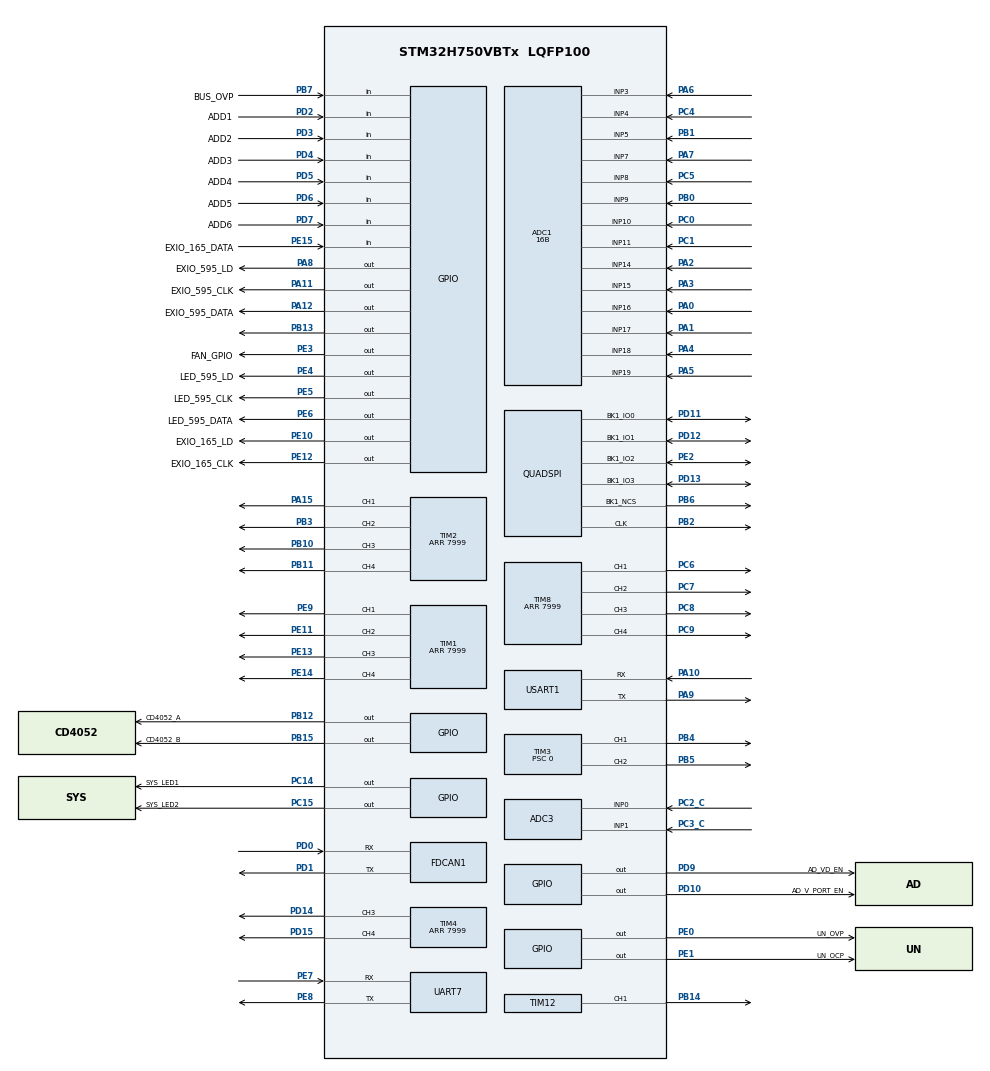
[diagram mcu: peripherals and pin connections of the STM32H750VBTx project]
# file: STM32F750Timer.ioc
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ADC1.Channel-1\#ChannelRegularConversion=ADC_CHANNEL_16
ADC1.Channel-10\#ChannelRegularConversion=ADC_CHANNEL_19
ADC1.Channel-11\#ChannelRegularConversion=ADC_CHANNEL_3
ADC1.Channel-12\#ChannelRegularConversion=ADC_CHANNEL_7
ADC1.Channel-13\#ChannelRegularConversion=ADC_CHANNEL_4
ADC1.Channel-14\#ChannelRegularConversion=ADC_CHANNEL_8
ADC1.Channel-15\#ChannelRegularConversion=ADC_CHANNEL_9
ADC1.Channel-16\#ChannelRegularConversion=ADC_CHANNEL_5
ADC1.Channel-17\#ChannelRegularConversion=ADC_CHANNEL_10
ADC1.Channel-18\#ChannelRegularConversion=ADC_CHANNEL_11
ADC1.Channel-6\#ChannelRegularConversion=ADC_CHANNEL_17
ADC1.Channel-7\#ChannelRegularConversion=ADC_CHANNEL_14
ADC1.Channel-8\#ChannelRegularConversion=ADC_CHANNEL_15
ADC1.Channel-9\#ChannelRegularConversion=ADC_CHANNEL_18
ADC1.ClockPrescaler=ADC_CLOCK_ASYNC_DIV1
ADC1.ClockPrescalerADC3=ADC_CLOCK_ASYNC_DIV2
ADC1.ContinuousConvMode=ENABLE
ADC1.ConversionDataManagement=ADC_CONVERSIONDATA_DMA_CIRCULAR
ADC1.EOCSelection=ADC_EOC_SEQ_CONV
ADC1.EnableInjectedConversion=DISABLE
ADC1.EnableInjectedOversampling=DISABLE
ADC1.ExternalTrigConv=ADC_SOFTWARE_START
ADC1.NbrOfConversion=14
ADC1.NbrOfConversionFlag=1
ADC1.OffsetNumber-1\#ChannelRegularConversion=ADC_OFFSET_NONE
ADC1.OffsetNumber-10\#ChannelRegularConversion=ADC_OFFSET_NONE
ADC1.OffsetNumber-11\#ChannelRegularConversion=ADC_OFFSET_NONE
ADC1.OffsetNumber-12\#ChannelRegularConversion=ADC_OFFSET_NONE
ADC1.OffsetNumber-13\#ChannelRegularConversion=ADC_OFFSET_NONE
ADC1.OffsetNumber-14\#ChannelRegularConversion=ADC_OFFSET_NONE
ADC1.OffsetNumber-15\#ChannelRegularConversion=ADC_OFFSET_NONE
ADC1.OffsetNumber-16\#ChannelRegularConversion=ADC_OFFSET_NONE
ADC1.OffsetNumber-17\#ChannelRegularConversion=ADC_OFFSET_NONE
ADC1.OffsetNumber-18\#ChannelRegularConversion=ADC_OFFSET_NONE
ADC1.OffsetNumber-6\#ChannelRegularConversion=ADC_OFFSET_NONE
ADC1.OffsetNumber-7\#ChannelRegularConversion=ADC_OFFSET_NONE
ADC1.OffsetNumber-8\#ChannelRegularConversion=ADC_OFFSET_NONE
ADC1.OffsetNumber-9\#ChannelRegularConversion=ADC_OFFSET_NONE
ADC1.OffsetSignedSaturation-1\#ChannelRegularConversion=DISABLE
ADC1.OffsetSignedSaturation-10\#ChannelRegularConversion=DISABLE
ADC1.OffsetSignedSaturation-11\#ChannelRegularConversion=DISABLE
ADC1.OffsetSignedSaturation-12\#ChannelRegularConversion=DISABLE
ADC1.OffsetSignedSaturation-13\#ChannelRegularConversion=DISABLE
ADC1.OffsetSignedSaturation-14\#ChannelRegularConversion=DISABLE
ADC1.OffsetSignedSaturation-15\#ChannelRegularConversion=DISABLE
ADC1.OffsetSignedSaturation-16\#ChannelRegularConversion=DISABLE
ADC1.OffsetSignedSaturation-17\#ChannelRegularConversion=DISABLE
ADC1.OffsetSignedSaturation-18\#ChannelRegularConversion=DISABLE
ADC1.OffsetSignedSaturation-6\#ChannelRegularConversion=DISABLE
ADC1.OffsetSignedSaturation-7\#ChannelRegularConversion=DISABLE
ADC1.OffsetSignedSaturation-8\#ChannelRegularConversion=DISABLE
ADC1.OffsetSignedSaturation-9\#ChannelRegularConversion=DISABLE
ADC1.Rank-1\#ChannelRegularConversion=1
ADC1.Rank-10\#ChannelRegularConversion=6
ADC1.Rank-11\#ChannelRegularConversion=7
ADC1.Rank-12\#ChannelRegularConversion=8
ADC1.Rank-13\#ChannelRegularConversion=9
ADC1.Rank-14\#ChannelRegularConversion=10
ADC1.Rank-15\#ChannelRegularConversion=11
ADC1.Rank-16\#ChannelRegularConversion=12
ADC1.Rank-17\#ChannelRegularConversion=13
ADC1.Rank-18\#ChannelRegularConversion=14
ADC1.Rank-6\#ChannelRegularConversion=2
ADC1.Rank-7\#ChannelRegularConversion=3
ADC1.Rank-8\#ChannelRegularConversion=4
ADC1.Rank-9\#ChannelRegularConversion=5
ADC1.Resolution=ADC_RESOLUTION_16B
ADC1.SamplingTime-1\#ChannelRegularConversion=ADC_SAMPLETIME_16CYCLES_5
ADC1.SamplingTime-10\#ChannelRegularConversion=ADC_SAMPLETIME_16CYCLES_5
ADC1.SamplingTime-11\#ChannelRegularConversion=ADC_SAMPLETIME_16CYCLES_5
ADC1.SamplingTime-12\#ChannelRegularConversion=ADC_SAMPLETIME_16CYCLES_5
ADC1.SamplingTime-13\#ChannelRegularConversion=ADC_SAMPLETIME_16CYCLES_5
ADC1.SamplingTime-14\#ChannelRegularConversion=ADC_SAMPLETIME_16CYCLES_5
ADC1.SamplingTime-15\#ChannelRegularConversion=ADC_SAMPLETIME_16CYCLES_5
ADC1.SamplingTime-16\#ChannelRegularConversion=ADC_SAMPLETIME_16CYCLES_5
ADC1.SamplingTime-17\#ChannelRegularConversion=ADC_SAMPLETIME_16CYCLES_5
ADC1.SamplingTime-18\#ChannelRegularConversion=ADC_SAMPLETIME_16CYCLES_5
ADC1.SamplingTime-6\#ChannelRegularConversion=ADC_SAMPLETIME_16CYCLES_5
ADC1.SamplingTime-7\#ChannelRegularConversion=ADC_SAMPLETIME_16CYCLES_5
ADC1.SamplingTime-8\#ChannelRegularConversion=ADC_SAMPLETIME_810CYCLES_5
ADC1.SamplingTime-9\#ChannelRegularConversion=ADC_SAMPLETIME_16CYCLES_5
ADC1.master=1
ADC3.Channel-0\#ChannelRegularConversion=ADC_CHANNEL_0
ADC3.Channel-1\#ChannelRegularConversion=ADC_CHANNEL_1
ADC3.ClockPrescalerADC3=ADC_CLOCK_ASYNC_DIV2
ADC3.ContinuousConvMode=ENABLE
ADC3.ConversionDataManagement=ADC_CONVERSIONDATA_DMA_CIRCULAR
ADC3.NbrOfConversion=2
ADC3.NbrOfConversionFlag=1
ADC3.OffsetNumber-0\#ChannelRegularConversion=ADC_OFFSET_NONE
ADC3.OffsetNumber-1\#ChannelRegularConversion=ADC_OFFSET_NONE
ADC3.OffsetSignedSaturation-0\#ChannelRegularConversion=DISABLE
ADC3.OffsetSignedSaturation-1\#ChannelRegularConversion=DISABLE
ADC3.Rank-0\#ChannelRegularConversion=1
ADC3.Rank-1\#ChannelRegularConversion=2
ADC3.SamplingTime-0\#ChannelRegularConversion=ADC_SAMPLETIME_810CYCLES_5
ADC3.SamplingTime-1\#ChannelRegularConversion=ADC_SAMPLETIME_810CYCLES_5
CORTEX_M7.default_mode_Activation=1
Dma.ADC1.2.Direction=DMA_PERIPH_TO_MEMORY
Dma.ADC1.2.EventEnable=DISABLE
Dma.ADC1.2.FIFOMode=DMA_FIFOMODE_DISABLE
Dma.ADC1.2.Instance=DMA1_Stream0
Dma.ADC1.2.MemDataAlignment=DMA_MDATAALIGN_HALFWORD
Dma.ADC1.2.MemInc=DMA_MINC_ENABLE
Dma.ADC1.2.Mode=DMA_CIRCULAR
Dma.ADC1.2.PeriphDataAlignment=DMA_PDATAALIGN_HALFWORD
Dma.ADC1.2.PeriphInc=DMA_PINC_DISABLE
Dma.ADC1.2.Polarity=HAL_DMAMUX_REQ_GEN_RISING
Dma.ADC1.2.Priority=DMA_PRIORITY_HIGH
Dma.ADC1.2.RequestNumber=1
Dma.ADC1.2.SignalID=NONE
Dma.ADC1.2.SyncEnable=DISABLE
Dma.ADC1.2.SyncPolarity=HAL_DMAMUX_SYNC_NO_EVENT
Dma.ADC1.2.SyncRequestNumber=1
Dma.ADC1.2.SyncSignalID=NONE
Dma.ADC3.3.Direction=DMA_PERIPH_TO_MEMORY
Dma.ADC3.3.EventEnable=DISABLE
Dma.ADC3.3.FIFOMode=DMA_FIFOMODE_DISABLE
Dma.ADC3.3.Instance=DMA1_Stream4
Dma.ADC3.3.MemDataAlignment=DMA_MDATAALIGN_HALFWORD
Dma.ADC3.3.MemInc=DMA_MINC_ENABLE
Dma.ADC3.3.Mode=DMA_CIRCULAR
Dma.ADC3.3.PeriphDataAlignment=DMA_PDATAALIGN_HALFWORD
Dma.ADC3.3.PeriphInc=DMA_PINC_DISABLE
Dma.ADC3.3.Polarity=HAL_DMAMUX_REQ_GEN_RISING
Dma.ADC3.3.Priority=DMA_PRIORITY_LOW
Dma.ADC3.3.RequestNumber=1
Dma.ADC3.3.SignalID=NONE
Dma.ADC3.3.SyncEnable=DISABLE
Dma.ADC3.3.SyncPolarity=HAL_DMAMUX_SYNC_NO_EVENT
Dma.ADC3.3.SyncRequestNumber=1
Dma.ADC3.3.SyncSignalID=NONE
Dma.Request0=USART1_RX
Dma.Request1=USART1_TX
Dma.Request2=ADC1
Dma.Request3=ADC3
Dma.Request4=UART7_RX
Dma.Request5=UART7_TX
Dma.UART7_RX.4.Direction=DMA_PERIPH_TO_MEMORY
Dma.UART7_RX.4.EventEnable=DISABLE
Dma.UART7_RX.4.FIFOMode=DMA_FIFOMODE_DISABLE
Dma.UART7_RX.4.Instance=DMA1_Stream1
Dma.UART7_RX.4.MemDataAlignment=DMA_MDATAALIGN_BYTE
Dma.UART7_RX.4.MemInc=DMA_MINC_ENABLE
Dma.UART7_RX.4.Mode=DMA_NORMAL
Dma.UART7_RX.4.PeriphDataAlignment=DMA_PDATAALIGN_BYTE
Dma.UART7_RX.4.PeriphInc=DMA_PINC_DISABLE
Dma.UART7_RX.4.Polarity=HAL_DMAMUX_REQ_GEN_RISING
Dma.UART7_RX.4.Priority=DMA_PRIORITY_LOW
Dma.UART7_RX.4.RequestNumber=1
Dma.UART7_RX.4.SignalID=NONE
Dma.UART7_RX.4.SyncEnable=DISABLE
Dma.UART7_RX.4.SyncPolarity=HAL_DMAMUX_SYNC_NO_EVENT
Dma.UART7_RX.4.SyncRequestNumber=1
Dma.UART7_RX.4.SyncSignalID=NONE
Dma.UART7_TX.5.Direction=DMA_MEMORY_TO_PERIPH
Dma.UART7_TX.5.EventEnable=DISABLE
Dma.UART7_TX.5.FIFOMode=DMA_FIFOMODE_DISABLE
Dma.UART7_TX.5.Instance=DMA1_Stream3
Dma.UART7_TX.5.MemDataAlignment=DMA_MDATAALIGN_BYTE
Dma.UART7_TX.5.MemInc=DMA_MINC_ENABLE
Dma.UART7_TX.5.Mode=DMA_NORMAL
Dma.UART7_TX.5.PeriphDataAlignment=DMA_PDATAALIGN_BYTE
Dma.UART7_TX.5.PeriphInc=DMA_PINC_DISABLE
Dma.UART7_TX.5.Polarity=HAL_DMAMUX_REQ_GEN_RISING
Dma.UART7_TX.5.Priority=DMA_PRIORITY_LOW
Dma.UART7_TX.5.RequestNumber=1
Dma.UART7_TX.5.SignalID=NONE
Dma.UART7_TX.5.SyncEnable=DISABLE
Dma.UART7_TX.5.SyncPolarity=HAL_DMAMUX_SYNC_NO_EVENT
Dma.UART7_TX.5.SyncRequestNumber=1
Dma.UART7_TX.5.SyncSignalID=NONE
Dma.USART1_RX.0.Direction=DMA_PERIPH_TO_MEMORY
Dma.USART1_RX.0.EventEnable=DISABLE
Dma.USART1_RX.0.FIFOMode=DMA_FIFOMODE_DISABLE
Dma.USART1_RX.0.Instance=DMA1_Stream2
Dma.USART1_RX.0.MemDataAlignment=DMA_MDATAALIGN_BYTE
Dma.USART1_RX.0.MemInc=DMA_MINC_ENABLE
Dma.USART1_RX.0.Mode=DMA_NORMAL
Dma.USART1_RX.0.PeriphDataAlignment=DMA_PDATAALIGN_BYTE
Dma.USART1_RX.0.PeriphInc=DMA_PINC_DISABLE
Dma.USART1_RX.0.Polarity=HAL_DMAMUX_REQ_GEN_RISING
Dma.USART1_RX.0.Priority=DMA_PRIORITY_LOW
Dma.USART1_RX.0.RequestNumber=1
Dma.USART1_RX.0.SignalID=NONE
Dma.USART1_RX.0.SyncEnable=DISABLE
Dma.USART1_RX.0.SyncPolarity=HAL_DMAMUX_SYNC_NO_EVENT
Dma.USART1_RX.0.SyncRequestNumber=1
Dma.USART1_RX.0.SyncSignalID=NONE
Dma.USART1_TX.1.Direction=DMA_MEMORY_TO_PERIPH
Dma.USART1_TX.1.EventEnable=DISABLE
Dma.USART1_TX.1.FIFOMode=DMA_FIFOMODE_DISABLE
Dma.USART1_TX.1.Instance=DMA1_Stream7
Dma.USART1_TX.1.MemDataAlignment=DMA_MDATAALIGN_BYTE
Dma.USART1_TX.1.MemInc=DMA_MINC_ENABLE
Dma.USART1_TX.1.Mode=DMA_NORMAL
Dma.USART1_TX.1.PeriphDataAlignment=DMA_PDATAALIGN_BYTE
Dma.USART1_TX.1.PeriphInc=DMA_PINC_DISABLE
Dma.USART1_TX.1.Polarity=HAL_DMAMUX_REQ_GEN_RISING
Dma.USART1_TX.1.Priority=DMA_PRIORITY_LOW
Dma.USART1_TX.1.RequestNumber=1
Dma.USART1_TX.1.SignalID=NONE
Dma.USART1_TX.1.SyncEnable=DISABLE
Dma.USART1_TX.1.SyncPolarity=HAL_DMAMUX_SYNC_NO_EVENT
Dma.USART1_TX.1.SyncRequestNumber=1
Dma.USART1_TX.1.SyncSignalID=NONE
FDCAN1.AutoRetransmission=ENABLE
FDCAN1.CalculateBaudRateNominal=499999
FDCAN1.CalculateTimeBitNominal=2000
FDCAN1.CalculateTimeQuantumNominal=166.66666666666669
FDCAN1.ExtFiltersNbr=10
FDCAN1.NominalPrescaler=20
FDCAN1.NominalTimeSeg1=10
FDCAN1.RxBuffersNbr=8
FDCAN1.RxFifo0ElmtsNbr=16
FDCAN1.RxFifo1ElmtsNbr=16
FDCAN1.TxBuffersNbr=10
FDCAN1.TxEventsNbr=10
FDCAN1.TxFifoQueueElmtsNbr=1
Mcu.Family=STM32H7
Mcu.Name=STM32H750VBTx
Mcu.Package=LQFP100
NVIC.DMA1_Stream0_IRQn=true\:0\:0\:false\:false\:true\:false\:true\:true
NVIC.DMA1_Stream1_IRQn=true\:0\:0\:false\:false\:true\:false\:true\:true
NVIC.DMA1_Stream2_IRQn=true\:0\:0\:false\:false\:true\:false\:true\:true
NVIC.DMA1_Stream3_IRQn=true\:0\:0\:false\:false\:true\:false\:true\:true
NVIC.DMA1_Stream4_IRQn=true\:0\:0\:false\:false\:true\:false\:true\:true
NVIC.DMA1_Stream7_IRQn=true\:0\:0\:false\:false\:true\:false\:true\:true
NVIC.FDCAN1_IT0_IRQn=true\:0\:0\:false\:false\:true\:true\:true\:true
NVIC.FDCAN1_IT1_IRQn=true\:0\:0\:false\:false\:true\:true\:true\:true
NVIC.PriorityGroup=NVIC_PRIORITYGROUP_4
NVIC.TIM6_DAC_IRQn=true\:0\:0\:false\:false\:true\:true\:true\:true
NVIC.TIM7_IRQn=true\:0\:0\:false\:false\:true\:true\:true\:true
NVIC.UART7_IRQn=true\:0\:0\:false\:false\:true\:true\:true\:true
NVIC.USART1_IRQn=true\:0\:0\:false\:false\:true\:true\:true\:true
PA0.Mode=IN16-Single-Ended
PA0.Signal=ADC1_INP16
PA1.Signal=SharedAnalog_PA1
PA10.GPIO_PuPd=GPIO_PULLUP
PA10.GPIO_Speed=GPIO_SPEED_FREQ_HIGH
PA10.Mode=Asynchronous
PA10.Signal=USART1_RX
PA11.GPIO_Label=EXIO_595_CLK
PA11.Signal=GPIO_Output
PA12.GPIO_Label=EXIO_595_DATA
PA12.Signal=GPIO_Output
PA13\ (JTMS/SWDIO).Mode=Serial_Wire
PA13\ (JTMS/SWDIO).Signal=DEBUG_JTMS-SWDIO
PA14\ (JTCK/SWCLK).Mode=Serial_Wire
PA14\ (JTCK/SWCLK).Signal=DEBUG_JTCK-SWCLK
PA15\ (JTDI).Signal=S_TIM2_CH1_ETR
PA2.Signal=ADCx_INP14
PA3.Signal=ADCx_INP15
PA4.Signal=ADCx_INP18
PA5.Signal=ADCx_INP19
PA6.Signal=ADCx_INP3
PA7.Signal=ADCx_INP7
PA8.GPIO_Label=EXIO_595_LD
PA8.GPIO_Speed=GPIO_SPEED_FREQ_MEDIUM
PA8.Signal=GPIO_Output
PA9.GPIO_PuPd=GPIO_PULLUP
PA9.GPIO_Speed=GPIO_SPEED_FREQ_HIGH
PA9.Mode=Asynchronous
PA9.Signal=USART1_TX
PB0.Signal=SharedAnalog_PB0
PB1.Signal=ADCx_INP5
PB10.Signal=S_TIM2_CH3
PB11.Signal=S_TIM2_CH4
PB12.GPIO_Label=CD4052_A
PB12.Signal=GPIO_Output
PB13.Signal=GPIO_Output
PB14.Signal=S_TIM12_CH1
PB15.GPIO_Label=CD4052_B
PB15.Signal=GPIO_Output
PB2.Mode=Single Bank 1
PB2.Signal=QUADSPI_CLK
PB3\ (JTDO/TRACESWO).Signal=S_TIM2_CH2
PB4\ (NJTRST).Signal=S_TIM3_CH1
PB5.Signal=S_TIM3_CH2
PB6.Mode=Single Bank 1
PB6.Signal=QUADSPI_BK1_NCS
PB7.GPIO_Label=BUS_OVP
PB7.Signal=GPIO_Input
PB9.Signal=I2C4_SDA
PC0.Signal=ADCx_INP10
PC1.Signal=ADCx_INP11
PC14-OSC32_IN\ (OSC32_IN).GPIO_Label=SYS_LED1
PC14-OSC32_IN\ (OSC32_IN).GPIO_PuPd=GPIO_PULLUP
PC14-OSC32_IN\ (OSC32_IN).Signal=GPIO_Output
PC15-OSC32_OUT\ (OSC32_OUT).GPIO_Label=SYS_LED2
PC15-OSC32_OUT\ (OSC32_OUT).GPIO_ModeDefaultOutputPP=GPIO_MODE_OUTPUT_PP
PC15-OSC32_OUT\ (OSC32_OUT).GPIO_PuPd=GPIO_PULLUP
PC15-OSC32_OUT\ (OSC32_OUT).Signal=GPIO_Output
PC2_C.Mode=IN0-Single-Ended
PC2_C.Signal=ADC3_INP0
PC3_C.Mode=IN1-Single-Ended
PC3_C.Signal=ADC3_INP1
PC4.Signal=ADCx_INP4
PC5.Signal=ADCx_INP8
PC6.Signal=S_TIM8_CH1
PC7.Signal=S_TIM8_CH2
PC8.Signal=S_TIM8_CH3
PC9.Signal=S_TIM8_CH4
PD0.Mode=FDCAN_Activate
PD0.Signal=FDCAN1_RX
PD1.Mode=FDCAN_Activate
PD1.Signal=FDCAN1_TX
PD10.GPIO_Label=AD_V_PORT_EN
PD10.Signal=GPIO_Output
PD11.Mode=Single Bank 1
PD11.Signal=QUADSPI_BK1_IO0
PD12.Mode=Single Bank 1
PD12.Signal=QUADSPI_BK1_IO1
PD13.Mode=Single Bank 1
PD13.Signal=QUADSPI_BK1_IO3
PD14.Signal=S_TIM4_CH3
PD15.Signal=S_TIM4_CH4
PD2.GPIO_Label=ADD1
PD2.Signal=GPIO_Input
PD3.GPIO_Label=ADD2
PD3.Signal=GPIO_Input
PD4.GPIO_Label=ADD3
PD4.Signal=GPIO_Input
PD5.GPIO_Label=ADD4
PD5.Signal=GPIO_Input
PD6.GPIO_Label=ADD5
PD6.Signal=GPIO_Input
PD7.GPIO_Label=ADD6
PD7.Signal=GPIO_Input
PD9.GPIO_Label=AD_VD_EN
PD9.Signal=GPIO_Output
PE0.GPIO_Label=UN_OVP
PE0.Signal=GPIO_Output
PE1.GPIO_Label=UN_OCP
PE1.GPIO_PuPd=GPIO_PULLUP
PE1.GPIO_Speed=GPIO_SPEED_FREQ_HIGH
PE1.Signal=GPIO_Output
PE10.GPIO_Label=EXIO_165_LD
PE10.Signal=GPIO_Output
PE11.Signal=S_TIM1_CH2
PE12.GPIO_Label=EXIO_165_CLK
PE12.Signal=GPIO_Output
PE13.Signal=S_TIM1_CH3
PE14.Signal=S_TIM1_CH4
PE15.GPIO_Label=EXIO_165_DATA
PE15.Signal=GPIO_Input
PE2.Mode=Single Bank 1
PE2.Signal=QUADSPI_BK1_IO2
PE3.GPIO_Label=FAN_GPIO
PE3.Signal=GPIO_Output
PE4.GPIO_Label=LED_595_LD
PE4.Signal=GPIO_Output
PE5.GPIO_Label=LED_595_CLK
PE5.GPIO_PuPd=GPIO_PULLUP
PE5.GPIO_Speed=GPIO_SPEED_FREQ_LOW
PE5.Signal=GPIO_Output
PE6.GPIO_Label=LED_595_DATA
PE6.Signal=GPIO_Output
PE7.Mode=Asynchronous
PE7.Signal=UART7_RX
PE8.Mode=Asynchronous
PE8.Signal=UART7_TX
PE9.Signal=S_TIM1_CH1
PH0-OSC_IN\ (PH0).Mode=HSE-External-Oscillator
PH0-OSC_IN\ (PH0).Signal=RCC_OSC_IN
PH1-OSC_OUT\ (PH1).Mode=HSE-External-Oscillator
PH1-OSC_OUT\ (PH1).Signal=RCC_OSC_OUT
ProjectManager.HeapSize=0x1800
ProjectManager.StackSize=0x1800
ProjectManager.TargetToolchain=MDK-ARM V5.32
QUADSPI.ChipSelectHighTime=QSPI_CS_HIGH_TIME_6_CYCLE
QUADSPI.ClockPrescaler=6
QUADSPI.FifoThreshold=4
QUADSPI.FlashSize=24
QUADSPI.SampleShifting=QSPI_SAMPLE_SHIFTING_HALFCYCLE
RCC.ADCFreq_Value=75000000
RCC.APB1Freq_Value=120000000
RCC.APB2Freq_Value=120000000
RCC.APB3Freq_Value=120000000
RCC.APB4Freq_Value=120000000
RCC.CortexFreq_Value=480000000
RCC.D1PPRE=RCC_APB3_DIV2
RCC.D2PPRE1=RCC_APB1_DIV2
RCC.D2PPRE2=RCC_APB2_DIV2
RCC.D3PPRE=RCC_APB4_DIV2
RCC.DIVM1=5
RCC.DIVM2=2
RCC.DIVN1=192
RCC.DIVN2=12
RCC.DIVQ1=8
RCC.HCLKFreq_Value=240000000
RCC.HPRE=RCC_HCLK_DIV2
RCC.PLL2FRACN=0
RCC.PLL3FRACN=0
RCC.PLLFRACN=0
RCC.PLLSourceVirtual=RCC_PLLSOURCE_HSE
RCC.SYSCLKFreq_VALUE=480000000
RCC.SYSCLKSource=RCC_SYSCLKSOURCE_PLLCLK
RCC.USBFreq_Value=120000000
SH.ADCx_INP10.0=ADC1_INP10,IN10-Single-Ended
SH.ADCx_INP10.1=ADC3_INP10
SH.ADCx_INP11.0=ADC1_INP11,IN11-Single-Ended
SH.ADCx_INP14.0=ADC1_INP14,IN14-Single-Ended
SH.ADCx_INP15.0=ADC1_INP15,IN15-Single-Ended
SH.ADCx_INP18.0=ADC1_INP18,IN18-Single-Ended
SH.ADCx_INP19.0=ADC1_INP19,IN19-Single-Ended
SH.ADCx_INP3.0=ADC1_INP3,IN3-Single-Ended
SH.ADCx_INP4.0=ADC1_INP4,IN4-Single-Ended
SH.ADCx_INP5.0=ADC1_INP5,IN5-Single-Ended
SH.ADCx_INP7.0=ADC1_INP7,IN7-Single-Ended
SH.ADCx_INP8.0=ADC1_INP8,IN8-Single-Ended
SH.S_TIM12_CH1.0=TIM12_CH1,PWM Generation1 CH1
SH.S_TIM1_CH1.0=TIM1_CH1,PWM Generation1 CH1
SH.S_TIM1_CH2.0=TIM1_CH2,PWM Generation2 CH2
SH.S_TIM1_CH3.0=TIM1_CH3,PWM Generation3 CH3
SH.S_TIM1_CH4.0=TIM1_CH4,PWM Generation4 CH4
SH.S_TIM2_CH1_ETR.0=TIM2_CH1,PWM Generation1 CH1
SH.S_TIM2_CH2.0=TIM2_CH2,PWM Generation2 CH2
SH.S_TIM2_CH3.0=TIM2_CH3,PWM Generation3 CH3
SH.S_TIM2_CH4.0=TIM2_CH4,PWM Generation4 CH4
SH.S_TIM3_CH1.0=TIM3_CH1,PWM Generation1 CH1
SH.S_TIM3_CH2.0=TIM3_CH2,PWM Generation2 CH2
SH.S_TIM4_CH3.0=TIM4_CH3,PWM Generation3 CH3
SH.S_TIM4_CH4.0=TIM4_CH4,PWM Generation4 CH4
SH.S_TIM8_CH1.0=TIM8_CH1,PWM Generation1 CH1
SH.S_TIM8_CH2.0=TIM8_CH2,PWM Generation2 CH2
SH.S_TIM8_CH3.0=TIM8_CH3,PWM Generation3 CH3
SH.S_TIM8_CH4.0=TIM8_CH4,PWM Generation4 CH4
SH.SharedAnalog_PA1.0=ADC1_INN16
SH.SharedAnalog_PA1.1=ADC1_INP17,IN17-Single-Ended
SH.SharedAnalog_PB0.0=ADC1_INN5
SH.SharedAnalog_PB0.1=ADC1_INP9,IN9-Single-Ended
TIM1.AutoReloadPreload=TIM_AUTORELOAD_PRELOAD_ENABLE
TIM1.Channel-PWM\ Generation1\ CH1=TIM_CHANNEL_1
TIM1.Channel-PWM\ Generation2\ CH2=TIM_CHANNEL_2
TIM1.Channel-PWM\ Generation3\ CH3=TIM_CHANNEL_3
TIM1.Channel-PWM\ Generation4\ CH4=TIM_CHANNEL_4
TIM1.Period=7999
TIM1.Pulse-PWM\ Generation1\ CH1=200
TIM1.Pulse-PWM\ Generation2\ CH2=200
TIM1.Pulse-PWM\ Generation3\ CH3=200
TIM1.Pulse-PWM\ Generation4\ CH4=200
TIM1.RepetitionCounter=0
TIM12.AutoReloadPreload=TIM_AUTORELOAD_PRELOAD_ENABLE
TIM12.Channel-PWM\ Generation1\ CH1=TIM_CHANNEL_1
TIM12.Period=7999
TIM12.Pulse-PWM\ Generation1\ CH1=4000
TIM2.AutoReloadPreload=TIM_AUTORELOAD_PRELOAD_ENABLE
TIM2.Channel-PWM\ Generation1\ CH1=TIM_CHANNEL_1
TIM2.Channel-PWM\ Generation2\ CH2=TIM_CHANNEL_2
TIM2.Channel-PWM\ Generation3\ CH3=TIM_CHANNEL_3
TIM2.Channel-PWM\ Generation4\ CH4=TIM_CHANNEL_4
TIM2.Period=7999
TIM2.Pulse-PWM\ Generation1\ CH1=200
TIM2.Pulse-PWM\ Generation2\ CH2=200
TIM2.Pulse-PWM\ Generation3\ CH3=200
TIM2.Pulse-PWM\ Generation4\ CH4=200
TIM3.AutoReloadPreload=TIM_AUTORELOAD_PRELOAD_ENABLE
TIM3.Channel-PWM\ Generation1\ CH1=TIM_CHANNEL_1
TIM3.Channel-PWM\ Generation2\ CH2=TIM_CHANNEL_2
TIM3.Period=7999
TIM3.Prescaler=0
TIM3.Pulse-PWM\ Generation1\ CH1=200
TIM4.AutoReloadPreload=TIM_AUTORELOAD_PRELOAD_ENABLE
TIM4.Channel-PWM\ Generation3\ CH3=TIM_CHANNEL_3
TIM4.Channel-PWM\ Generation4\ CH4=TIM_CHANNEL_4
TIM4.Period=7999
TIM4.Pulse-PWM\ Generation3\ CH3=200
TIM6.AutoReloadPreload=TIM_AUTORELOAD_PRELOAD_ENABLE
TIM6.Period=2999
TIM6.Prescaler=7
TIM7.AutoReloadPreload=TIM_AUTORELOAD_PRELOAD_ENABLE
TIM7.Period=999
TIM7.Prescaler=9599
TIM8.AutoReloadPreload=TIM_AUTORELOAD_PRELOAD_ENABLE
TIM8.Channel-PWM\ Generation1\ CH1=TIM_CHANNEL_1
TIM8.Channel-PWM\ Generation2\ CH2=TIM_CHANNEL_2
TIM8.Channel-PWM\ Generation3\ CH3=TIM_CHANNEL_3
TIM8.Channel-PWM\ Generation4\ CH4=TIM_CHANNEL_4
TIM8.Period=7999
TIM8.Pulse-PWM\ Generation1\ CH1=200
TIM8.Pulse-PWM\ Generation2\ CH2=200
TIM8.Pulse-PWM\ Generation3\ CH3=200
TIM8.Pulse-PWM\ Generation4\ CH4=200
USART1.VirtualMode-Asynchronous=VM_ASYNC
VP_MEMORYMAP_VS_MEMORYMAP.Mode=CurAppReg
VP_TIM12_VS_ClockSourceINT.Mode=Internal
VP_TIM1_VS_ClockSourceINT.Mode=Internal
VP_TIM2_VS_ClockSourceINT.Mode=Internal
VP_TIM3_VS_ClockSourceINT.Mode=Internal
VP_TIM4_VS_ClockSourceINT.Mode=Internal
VP_TIM5_VS_ClockSourceINT.Mode=Internal
VP_TIM6_VS_ClockSourceINT.Mode=Enable_Timer
VP_TIM7_VS_ClockSourceINT.Mode=Enable_Timer
VP_TIM8_VS_ClockSourceINT.Mode=Internal
board=custom

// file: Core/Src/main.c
/* USER CODE BEGIN Header */
/**
 ******************************************************************************
 * @file           : main.c
 * @brief          : Main program body
 ******************************************************************************
 * @attention
 *
 * Copyright (c) 2025 STMicroelectronics.
 * All rights reserved.
 *
 * This software is licensed under terms that can be found in the LICENSE file
 * in the root directory of this software component.
 * If no LICENSE file comes with this software, it is provided AS-IS.
 *
 ******************************************************************************
 */
/* USER CODE END Header */
#include "main.h"
#include "adc.h"
#include "dma.h"
#include "fdcan.h"
#include "memorymap.h"
#include "quadspi.h"
#include "tim.h"
#include "usart.h"
#include "gpio.h"

/* USER CODE BEGIN Includes */

#include <stdint.h>

#include <stdio.h>
#include <stdlib.h>
#include <string.h>

#include "message_handler.h"
#include "system_can_config.h"
#include "large_data_transfer.h"
#include "crc.h"
#include "message_handler.h"
#include "system_can_config.h"

#include "head.h"

/* USER CODE END Includes */

void SystemClock_Config(void);
void PeriphCommonClock_Config(void);
static void MPU_Config(void);
/* USER CODE BEGIN PFP */
// 传输完成回调
void OnTransferComplete(TransferStatus status);

extern void TEST_W25Q128(void);
// 数据接收回调
void OnDataReceived(uint16_t src_did, uint16_t session_id,
                    uint8_t *data, uint32_t size);

// 传输失败回调
void OnTransferFailed(uint16_t session_id, TransferStatus reason);
/* USER CODE END PFP */

/* USER CODE BEGIN 0 */

LargeDataFrame gLargeDataFrame;
/* USER CODE END 0 */

int main(void)
{

  /* MPU Configuration--------------------------------------------------------*/
  MPU_Config();

  /* MCU Configuration--------------------------------------------------------*/

  /* Reset of all peripherals, Initializes the Flash interface and the Systick. */
  HAL_Init();

  /* Configure the system clock */
  SystemClock_Config();

  /* Configure the peripherals common clocks */
  PeriphCommonClock_Config();

  /* USER CODE BEGIN SysInit */
  /* 设置NVIC优先级分组 */
  HAL_NVIC_SetPriorityGrouping(NVIC_PRIORITYGROUP_4);
  // 分组4：4位抢占优先级，0位子优先级（推荐用于STM32H7）
  /* USER CODE END SysInit */

  /* Initialize all configured peripherals */
  MX_GPIO_Init();
  MX_DMA_Init();
  MX_TIM1_Init();
  MX_USART1_UART_Init();
  MX_TIM3_Init();
  MX_ADC1_Init();
  MX_FDCAN1_Init();
  MX_TIM2_Init();
  MX_TIM8_Init();
  MX_ADC3_Init();
//  MX_QUADSPI_Init();
  MX_TIM4_Init();
  MX_UART7_Init();
  MX_TIM5_Init();
  MX_TIM6_Init();
  MX_TIM12_Init();
  MX_TIM7_Init();
  /* USER CODE BEGIN 2 */

  AppUser_prvSetupHardware();

  Display_PeriphCLKFreq();

  RS485_ModbusCmdTask("CmdTask"); // RS485通讯解初始化

  AppUser_Device_InitData();

#if 1

  	 TEST_W25Q128();
//	SysTick_Init(systick_isr);   //SysTick定时器初始化
//   发送初始消息 (设备上线通知)   ad failed with erro
  uint8_t init_msg[4] = {0xAA, 0x55, 0x01, 0x23};
  FDCAN_SendMessage(FC_BROADCAST, BROADCAST_DEVICE_ID, 0x000, init_msg, sizeof(init_msg));
  CAN1_Send_TEST();
#endif

  App_Drive_InitTimer_7(); // 100ms
  Debug_PWM();
  STM32H750_UID();
  while (1)
  {

    UserSlave_Update();
    AppUser_PortocolRecv(); // MCU通讯协议包
    AppDebug_vTask();
    // AppUser_temp_sample();
    // Read_GPIO_vTask();

    Power_Stop_PWM();
  }

  /* USER CODE END 2 */

  /* Infinite loop */
  /* USER CODE BEGIN WHILE */
  //    while (1)
  //    {
    /* USER CODE END WHILE */

    /* USER CODE BEGIN 3 */

  //        /* USER CODE BEGIN 5 */
  //
  //        HAL_GPIO_WritePin(GPIOE, GPIO_PIN_2, 1);
  //        /* USER CODE END 5 */

  //    }
  /* USER CODE END 3 */
}

void SystemClock_Config(void)
{
  RCC_OscInitTypeDef RCC_OscInitStruct = {0};
  RCC_ClkInitTypeDef RCC_ClkInitStruct = {0};

  /** Supply configuration update enable
  */
  HAL_PWREx_ConfigSupply(PWR_LDO_SUPPLY);

  /** Configure the main internal regulator output voltage
  */
  __HAL_PWR_VOLTAGESCALING_CONFIG(PWR_REGULATOR_VOLTAGE_SCALE0);

  while(!__HAL_PWR_GET_FLAG(PWR_FLAG_VOSRDY)) {}

  /** Initializes the RCC Oscillators according to the specified parameters
  * in the RCC_OscInitTypeDef structure.
  */
  RCC_OscInitStruct.OscillatorType = RCC_OSCILLATORTYPE_HSE;
  RCC_OscInitStruct.HSEState = RCC_HSE_ON;
  RCC_OscInitStruct.PLL.PLLState = RCC_PLL_ON;
  RCC_OscInitStruct.PLL.PLLSource = RCC_PLLSOURCE_HSE;
  RCC_OscInitStruct.PLL.PLLM = 4;//5
  RCC_OscInitStruct.PLL.PLLN = 162;//190
  RCC_OscInitStruct.PLL.PLLP = 2;
  RCC_OscInitStruct.PLL.PLLQ = 8;
  RCC_OscInitStruct.PLL.PLLR = 2;
  RCC_OscInitStruct.PLL.PLLRGE = RCC_PLL1VCIRANGE_2;
  RCC_OscInitStruct.PLL.PLLVCOSEL = RCC_PLL1VCOWIDE;
  RCC_OscInitStruct.PLL.PLLFRACN = 0;
  if (HAL_RCC_OscConfig(&RCC_OscInitStruct) != HAL_OK)
  {
    Error_Handler();
  }

  /** Initializes the CPU, AHB and APB buses clocks
  */
  RCC_ClkInitStruct.ClockType = RCC_CLOCKTYPE_HCLK|RCC_CLOCKTYPE_SYSCLK
                              |RCC_CLOCKTYPE_PCLK1|RCC_CLOCKTYPE_PCLK2
                              |RCC_CLOCKTYPE_D3PCLK1|RCC_CLOCKTYPE_D1PCLK1;
  RCC_ClkInitStruct.SYSCLKSource = RCC_SYSCLKSOURCE_PLLCLK;
  RCC_ClkInitStruct.SYSCLKDivider = RCC_SYSCLK_DIV1;
  RCC_ClkInitStruct.AHBCLKDivider = RCC_HCLK_DIV2;
  RCC_ClkInitStruct.APB3CLKDivider = RCC_APB3_DIV2;
  RCC_ClkInitStruct.APB1CLKDivider = RCC_APB1_DIV2;
  RCC_ClkInitStruct.APB2CLKDivider = RCC_APB2_DIV2;
  RCC_ClkInitStruct.APB4CLKDivider = RCC_APB4_DIV2;

  if (HAL_RCC_ClockConfig(&RCC_ClkInitStruct, FLASH_LATENCY_4) != HAL_OK)
  {
    Error_Handler();
  }
}

void PeriphCommonClock_Config(void)
{
  RCC_PeriphCLKInitTypeDef PeriphClkInitStruct = {0};

  /** Initializes the peripherals clock
  */
  PeriphClkInitStruct.PeriphClockSelection = RCC_PERIPHCLK_ADC;
  PeriphClkInitStruct.PLL2.PLL2M = 2;
  PeriphClkInitStruct.PLL2.PLL2N = 12;
  PeriphClkInitStruct.PLL2.PLL2P = 2;
  PeriphClkInitStruct.PLL2.PLL2Q = 2;
  PeriphClkInitStruct.PLL2.PLL2R = 2;
  PeriphClkInitStruct.PLL2.PLL2RGE = RCC_PLL2VCIRANGE_3;
  PeriphClkInitStruct.PLL2.PLL2VCOSEL = RCC_PLL2VCOMEDIUM;
  PeriphClkInitStruct.PLL2.PLL2FRACN = 0;
  PeriphClkInitStruct.AdcClockSelection = RCC_ADCCLKSOURCE_PLL2;
  if (HAL_RCCEx_PeriphCLKConfig(&PeriphClkInitStruct) != HAL_OK)
  {
    Error_Handler();
  }
}

/* USER CODE BEGIN 4 */
// uint8_t rx_data;
// HAL_UART_Receive_IT(&huart1, &rx_data, 1);

/* USER CODE END 4 */

 /* MPU Configuration */

void MPU_Config(void)
{
  MPU_Region_InitTypeDef MPU_InitStruct = {0};

  /* Disables the MPU */
  HAL_MPU_Disable();

  /** Initializes and configures the Region and the memory to be protected
  */
  MPU_InitStruct.Enable = MPU_REGION_ENABLE;
  MPU_InitStruct.Number = MPU_REGION_NUMBER0;
  MPU_InitStruct.BaseAddress = 0x0;
  MPU_InitStruct.Size = MPU_REGION_SIZE_4GB;
  MPU_InitStruct.SubRegionDisable = 0x87;
  MPU_InitStruct.TypeExtField = MPU_TEX_LEVEL0;
  MPU_InitStruct.AccessPermission = MPU_REGION_NO_ACCESS;
  MPU_InitStruct.DisableExec = MPU_INSTRUCTION_ACCESS_DISABLE;
  MPU_InitStruct.IsShareable = MPU_ACCESS_SHAREABLE;
  MPU_InitStruct.IsCacheable = MPU_ACCESS_NOT_CACHEABLE;
  MPU_InitStruct.IsBufferable = MPU_ACCESS_NOT_BUFFERABLE;

  HAL_MPU_ConfigRegion(&MPU_InitStruct);
  /* Enables the MPU */
  HAL_MPU_Enable(MPU_PRIVILEGED_DEFAULT);

}

void Error_Handler(void)
{
  __disable_irq();
  while (1)
  {
  }
}
